# R7FA6M4AF register map
Vendor: Renesas Electronics Corporation; Series: RA6; File version: 1.30.00
CPU: CM33 r0p4, little endian, MPU, FPU, VTOR, 4 interrupt priority bits, 96 interrupts
Registers are 8-bit, read-write, reset 0x0 unless marked. A register's access mark holds for its fields unless they carry their own. Offsets are from the block's base; [hi:lo] are bit positions; {n}, {i} and the like mark numbered series.

## SYSC — System Control
Base 0x4001E000
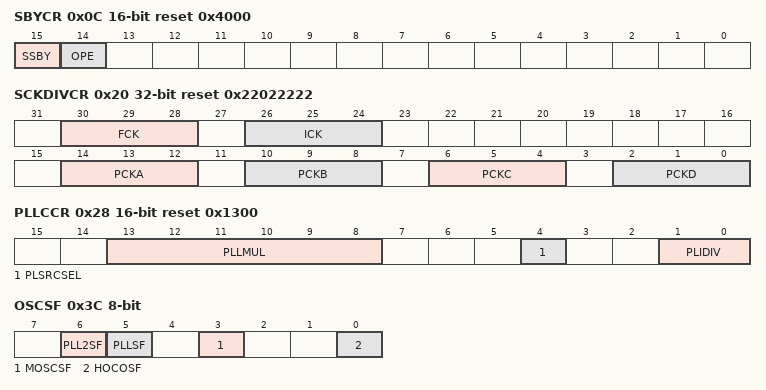
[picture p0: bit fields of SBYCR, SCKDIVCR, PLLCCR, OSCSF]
0x0C SBYCR 16-bit reset 0x4000 — Standby Control Register
  [15] SSBY — Software Standby Mode Select
  [14] OPE — Output Port Enable
0x20 SCKDIVCR 32-bit reset 0x22022222 — System Clock Division Control Register
  [30:28] FCK — FlashIF Clock (FCLK) Select
  [26:24] ICK — System Clock (ICLK) Select
  [14:12] PCKA — Peripheral Module Clock A (PCLKA) Select
  [10:8] PCKB — Peripheral Module Clock B (PCLKB) Select
  [6:4] PCKC — Peripheral Module Clock C (PCLKC) Select
  [2:0] PCKD — Peripheral Module Clock D (PCLKD) Select
0x26 SCKSCR reset 0x1 — System Clock Source Control Register
  [2:0] CKSEL — Clock Source Select
0x28 PLLCCR 16-bit reset 0x1300 — PLL Clock Control Register
  [13:8] PLLMUL range 0x13..0x3B — PLL Frequency Multiplication Factor Select
  [4] PLSRCSEL — PLL Clock Source Select
  [1:0] PLIDIV — PLL Input Frequency Division Ratio Select
0x2A PLLCR reset 0x1 — PLL Control Register
  [0] PLLSTP — PLL Stop Control
0x30 BCKCR — External Bus Clock Control Register
  [0] BCLKDIV — BCLK Pin Output Select
0x32 MOSCCR reset 0x1 — Main Clock Oscillator Control Register
  [0] MOSTP — Main Clock Oscillator Stop
0x36 HOCOCR (reset mask 0xFE) — High,Speed On,Chip Oscillator Control Register
  [0] HCSTP — HOCO Stop
0x38 MOCOCR — Middle,Speed On,Chip Oscillator Control Register
  [0] MCSTP — MOCO Stop
0x39 FLLCR1 — FLL Control Register1
  [0] FLLEN — FLL Enable
0x3A FLLCR2 16-bit — FLL Control Register2
  [10:0] FLLCNTL — FLL Multiplication Control
0x3C OSCSF ro (reset mask 0xFE) — Oscillation Stabilization Flag Register
  [6] PLL2SF — PLL2 Clock Oscillation Stabilization Flag
  [5] PLLSF — PLL Clock Oscillation Stabilization Flag
  [3] MOSCSF — Main Clock Oscillation Stabilization Flag
  [0] HOCOSF — HOCO Clock Oscillation Stabilization Flag
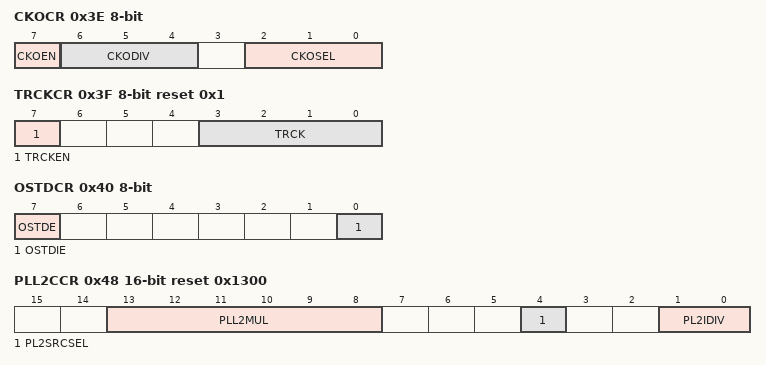
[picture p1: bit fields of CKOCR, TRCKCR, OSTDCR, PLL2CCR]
0x3E CKOCR — Clock Out Control Register
  [7] CKOEN — Clock Out Enable
  [6:4] CKODIV — Clock Output Frequency Division Ratio
  [2:0] CKOSEL — Clock Out Source Select
0x3F TRCKCR reset 0x1 — Trace Clock Control Register
  [7] TRCKEN — Trace Clock operating Enable
  [3:0] TRCK — Trace Clock operating frequency select
0x40 OSTDCR — Oscillation Stop Detection Control Register
  [7] OSTDE — Oscillation Stop Detection Function Enable
  [0] OSTDIE — Oscillation Stop Detection Interrupt Enable
0x41 OSTDSR — Oscillation Stop Detection Status Register
  [0] OSTDF — Oscillation Stop Detection Flag
0x48 PLL2CCR 16-bit reset 0x1300 — PLL2 Clock Control Register
  [13:8] PLL2MUL — PLL2 Frequency Multiplication Factor Select
  [4] PL2SRCSEL — PLL2 Clock Source Select
  [1:0] PL2IDIV — PLL2 Input Frequency Division Ratio Select
0x4A PLL2CR reset 0x1 — PLL2 Control Register
  [0] PLL2STP — PLL2 Stop Control
0x52 EBCKOCR — External Bus Clock Output Control Register
  [0] EBCKOEN — EBCLK Pin Output Control
0x61 MOCOUTCR — MOCO User Trimming Control Register
  [7:0] MOCOUTRM — MOCO User Trimming
0x62 HOCOUTCR — HOCO User Trimming Control Register
  [7:0] HOCOUTRM — HOCO User Trimming
0x6C USBCKDIVCR — USB Clock Division Control Register
  [2:0] USBCKDIV — USB Clock (USBCLK) Division Select
0x6D OCTACKDIVCR — Octal,SPI Clock Division Control Register
  [2:0] OCTACKDIV — Octal,SPI Clock (OCTACLK) Division Select
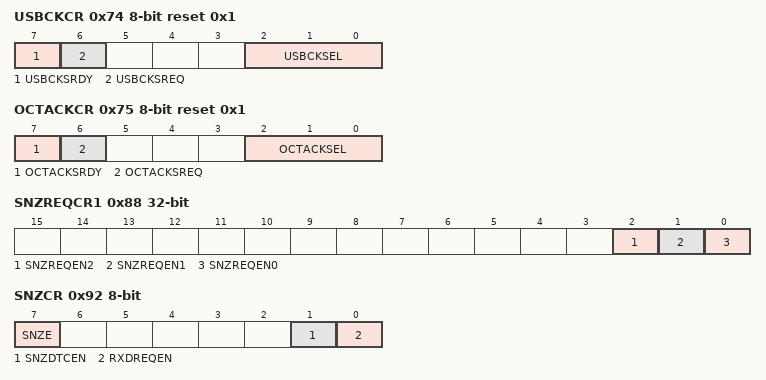
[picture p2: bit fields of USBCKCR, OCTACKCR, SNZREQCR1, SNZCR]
0x74 USBCKCR reset 0x1 — USB Clock Control Register
  [7] USBCKSRDY ro — USB Clock (USBCLK) Switching Ready state flag
  [6] USBCKSREQ — USB Clock (USBCLK) Switching Request
  [2:0] USBCKSEL — USB Clock (USBCLK) Source Select
0x75 OCTACKCR reset 0x1 — Octal,SPI Clock Control Register
  [7] OCTACKSRDY ro — Octal,SPI Clock (OCTACLK) Switching Ready state flag
  [6] OCTACKSREQ — Octal,SPI Clock (OCTACLK) Switching Request
  [2:0] OCTACKSEL — Octal,SPI Clock (OCTACLK) Source Select
0x88 SNZREQCR1 32-bit — Snooze Request Control Register 1
  [2] SNZREQEN2 — Enable AGT3 compare match B snooze request
  [1] SNZREQEN1 — Enable AGT3 compare match A snooze request
  [0] SNZREQEN0 — Enable AGT3 underflow snooze request
0x92 SNZCR — Snooze Control Register
  [7] SNZE — Snooze mode Enable
  [1] SNZDTCEN — DTC Enable in Snooze mode
  [0] RXDREQEN — RXD0 Snooze Request Enable
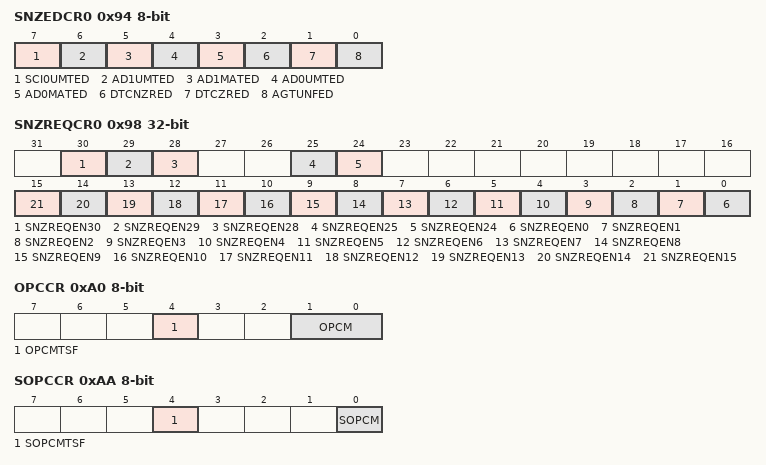
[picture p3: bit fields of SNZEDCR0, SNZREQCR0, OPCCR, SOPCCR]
0x94 SNZEDCR0 — Snooze End Control Register 0
  [7] SCI0UMTED — SCI0 Address Mismatch Snooze End Enable
  [6] AD1UMTED — ADC121 Compare Mismatch Snooze End Enable
  [5] AD1MATED — ADC121 Compare Match Snooze End Enable
  [4] AD0UMTED — ADC120 Compare Mismatch Snooze End Enable
  [3] AD0MATED — ADC120 Compare Match Snooze End Enable
  [2] DTCNZRED — Not Last DTC Transmission Completion Snooze End Enable
  [1] DTCZRED — Last DTC Transmission Completion Snooze End Enable
  [0] AGTUNFED — AGT1 Underflow Snooze End Enable
0x95 SNZEDCR1 — Snooze End Control Register 1
  [0] AGT3UNFED — AGT3 underflow Snooze End Enable
0x98 SNZREQCR0 32-bit — Snooze Request Control Register 0
  [30] SNZREQEN30 — Enable AGT1 compare match B snooze request
  [29] SNZREQEN29 — Enable AGT1 compare match A snooze request
  [28] SNZREQEN28 — Enable AGT1 underflow snooze request
  [25] SNZREQEN25 — Enable RTC period snooze request
  [24] SNZREQEN24 — Enable RTC alarm snooze request
  [n] SNZREQEN{n} (n=0..15) — Enable IRQ{n} pin snooze request
0xA0 OPCCR — Operating Power Control Register
  [4] OPCMTSF ro — Operating Power Control Mode Transition Status Flag
  [1:0] OPCM — Operating Power Control Mode Select
0xA2 MOSCWTCR reset 0x5 — Main Clock Oscillator Wait Control Register
  [3:0] MSTS — Main Clock Oscillator Wait Time Setting
0xAA SOPCCR — Sub Operating Power Control Register
  [4] SOPCMTSF ro — Operating Power Control Mode Transition Status Flag
  [0] SOPCM — Sub Operating Power Control Mode Select
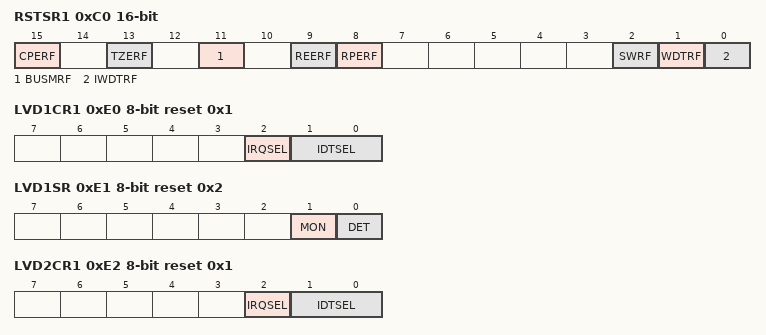
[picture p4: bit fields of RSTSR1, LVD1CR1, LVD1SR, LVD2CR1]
0xC0 RSTSR1 16-bit (reset mask 0x54F8) — Reset Status Register 1
  [15] CPERF — Cache Parity Error Reset Detect Flag
  [13] TZERF — TrustZone Error Reset Detect Flag
  [11] BUSMRF — Bus Master MPU Error Reset Detect Flag
  [9] REERF — SRAM ECC Error Reset Detect Flag
  [8] RPERF — SRAM Parity Error Reset Detect Flag
  [2] SWRF — Software Reset Detect Flag
  [1] WDTRF — Watchdog Timer Reset Detect Flag
  [0] IWDTRF — Independent Watchdog Timer Reset Detect Flag
0xE0 LVD1CR1 reset 0x1 — Voltage Monitor 1 Circuit Control Register
  [2] IRQSEL — Voltage Monitor 1 Interrupt Type Select
  [1:0] IDTSEL — Voltage Monitor 1 Interrupt Generation Condition Select
0xE1 LVD1SR reset 0x2 — Voltage Monitor 1 Circuit Status Register
  [1] MON ro — Voltage Monitor 1 Signal Monitor Flag
  [0] DET — Voltage Monitor 1 Voltage Variation Detection Flag
0xE2 LVD2CR1 reset 0x1 — Voltage Monitor 2 Circuit Control Register 1
  [2] IRQSEL — Voltage Monitor 2 Interrupt Type Select
  [1:0] IDTSEL — Voltage Monitor 2 Interrupt Generation Condition Select
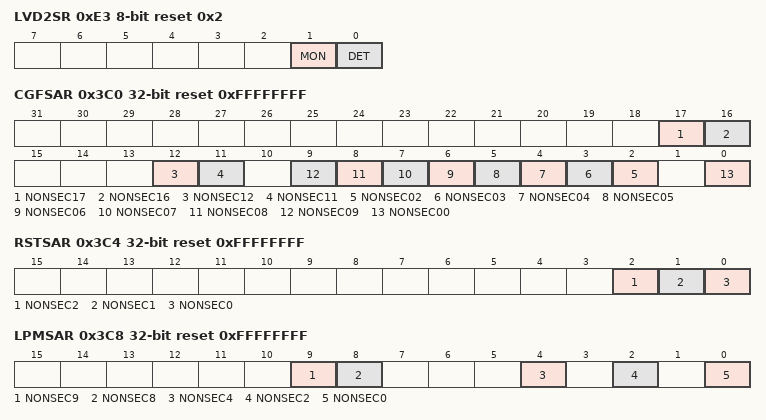
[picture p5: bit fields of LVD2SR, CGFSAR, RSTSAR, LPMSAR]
0xE3 LVD2SR reset 0x2 — Voltage Monitor 2 Circuit Status Register
  [1] MON ro — Voltage Monitor 2 Signal Monitor Flag
  [0] DET — Voltage Monitor 2 Voltage Variation Detection Flag
0x3C0 CGFSAR 32-bit reset 0xFFFFFFFF — Clock Generation Function Security Attribute Register
  [17] NONSEC17 — Non Secure Attribute bit 17
  [16] NONSEC16 — Non Secure Attribute bit 16
  [12] NONSEC12 — Non Secure Attribute bit 12
  [11] NONSEC11 — Non Secure Attribute bit 11
  [n] NONSEC{n:02} (n=2..9) — Non Secure Attribute bit {n:02}
  [0] NONSEC00 — Non Secure Attribute bit 00
0x3C4 RSTSAR 32-bit reset 0xFFFFFFFF — Reset Security Attribution Register
  [2] NONSEC2 — Non Secure Attribute bit 2
  [1] NONSEC1 — Non Secure Attribute bit 1
  [0] NONSEC0 — Non Secure Attribute bit 0
0x3C8 LPMSAR 32-bit reset 0xFFFFFFFF — Low Power Mode Security Attribution Register
  [9] NONSEC9 — Non Secure Attribute bit 9
  [8] NONSEC8 — Non Secure Attribute bit 8
  [4] NONSEC4 — Non Secure Attribute bit 4
  [2] NONSEC2 — Non Secure Attribute bit 2
  [0] NONSEC0 — Non Secure Attribute bit 0
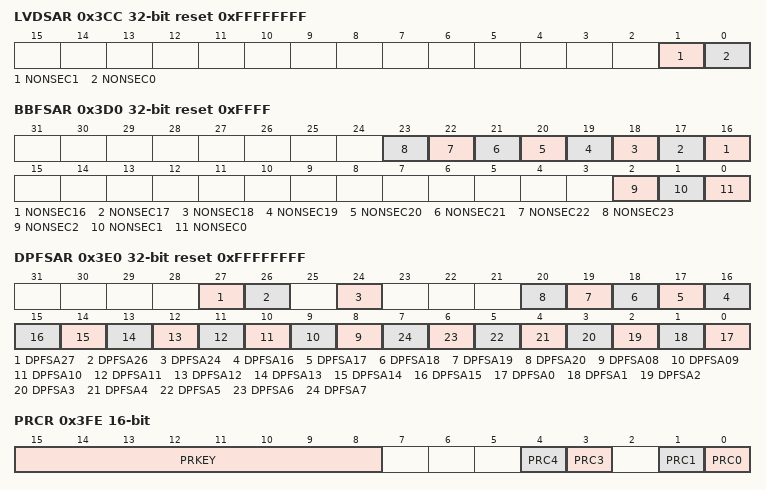
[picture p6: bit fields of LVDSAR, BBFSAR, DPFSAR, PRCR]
0x3CC LVDSAR 32-bit reset 0xFFFFFFFF — Low Voltage Detection Security Attribution Register
  [1] NONSEC1 — Non Secure Attribute bit 1
  [0] NONSEC0 — Non Secure Attribute bit 0
0x3D0 BBFSAR 32-bit reset 0xFFFF — Battery Backup Function Security Attribute Register
  [n] NONSEC{n} (n=16..23) — Non Secure Attribute bit {n}
  [2] NONSEC2 — Non Secure Attribute bit 2
  [1] NONSEC1 — Non Secure Attribute bit 1
  [0] NONSEC0 — Non Secure Attribute bit 0
0x3E0 DPFSAR 32-bit reset 0xFFFFFFFF — Deep Software Standby Interrupt Factor Security Attribution Register
  [27] DPFSA27 — Deep Software Standby Interrupt Factor Security Attribute bit 27
  [26] DPFSA26 — Deep Software Standby Interrupt Factor Security Attribute bit 26
  [24] DPFSA24 — Deep Software Standby Interrupt Factor Security Attribute bit 24
  [n] DPFSA{n} (n=16..20) — Deep Software Standby Interrupt Factor Security Attribute bit {n}
  [n] DPFSA{n:02} (n=8..15) — Deep Software Standby Interrupt Factor Security Attribute bit n (n = 8 to 15)
  [n] DPFSA{n} (n=0..7) — Deep Software Standby Interrupt Factor Security Attribute bit n (n = 0 to 7)
0x3FE PRCR 16-bit — Protect Register
  [15:8] PRKEY wo — PRC Key Code
  [4] PRC4
  [3] PRC3 — Enable writing to the registers related to the LVD
  [1] PRC1 — Enable writing to the registers related to the low power modes, and the battery backup function
  [0] PRC0 — Enable writing to the registers related to the clock generation circuit
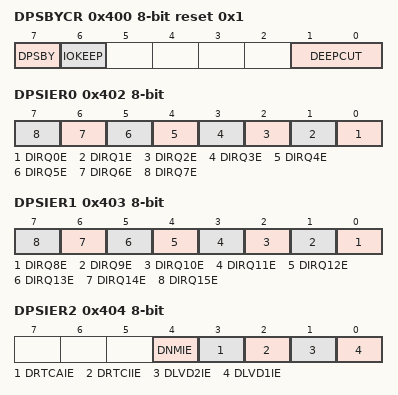
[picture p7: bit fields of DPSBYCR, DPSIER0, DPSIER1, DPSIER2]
0x400 DPSBYCR reset 0x1 — Deep Software Standby Control Register
  [7] DPSBY — Deep Software Standby
  [6] IOKEEP — I/O Port Retention
  [1:0] DEEPCUT — Power,Supply Control
0x401 DPSWCR reset 0x19 — Deep Software Standby Wait Control Register
  [5:0] WTSTS — Deep Software Wait Standby Time Setting Bit
0x402 DPSIER0 — Deep Software Standby Interrupt Enable Register 0
  [n] DIRQ{n}E (n=0..7) — IRQ{n}-DS Pin Enable
0x403 DPSIER1 — Deep Software Standby Interrupt Enable Register 1
  [n-8] DIRQ{n}E (n=8..15) — IRQ{n}-DS Pin Enable
0x404 DPSIER2 — Deep Software Standby Interrupt Enable Register 2
  [4] DNMIE — NMI Pin Enable
  [3] DRTCAIE — RTC Alarm interrupt Deep Software Standby Cancel Signal Enable
  [2] DRTCIIE — RTC Interval interrupt Deep Software Standby Cancel Signal Enable
  [1] DLVD2IE — LVD2 Deep Software Standby Cancel Signal Enable
  [0] DLVD1IE — LVD1 Deep Software Standby Cancel Signal Enable
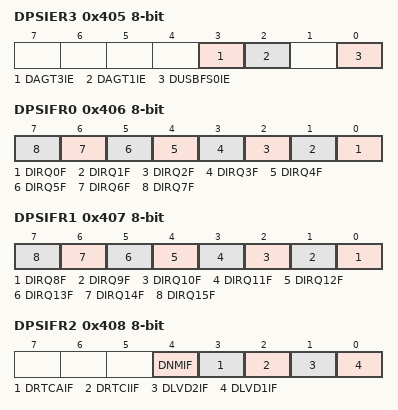
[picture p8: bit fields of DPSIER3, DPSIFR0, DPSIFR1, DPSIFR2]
0x405 DPSIER3 — Deep Software Standby Interrupt Enable Register 3
  [3] DAGT3IE — AGT3 Underflow Deep Software Standby Cancel Signal Enable
  [2] DAGT1IE — AGT1 Underflow Deep Software Standby Cancel Signal Enable
  [0] DUSBFS0IE — USBFS0 Suspend/Resume Deep Software Standby Cancel Signal Enable
0x406 DPSIFR0 — Deep Software Standby Interrupt Flag Register 0
  [n] DIRQ{n}F (n=0..7) — IRQ{n}-DS Pin Deep Software Standby Cancel Flag
0x407 DPSIFR1 — Deep Software Standby Interrupt Flag Register 1
  [n-8] DIRQ{n}F (n=8..15) — IRQ{n}-DS Pin Deep Software Standby Cancel Flag
0x408 DPSIFR2 — Deep Software Standby Interrupt Flag Register 2
  [4] DNMIF — NMI Pin Deep Software Standby Cancel Flag
  [3] DRTCAIF — RTC Alarm Interrupt Deep Software Standby Cancel Flag
  [2] DRTCIIF — RTC Interval Interrupt Deep Software Standby Cancel Flag
  [1] DLVD2IF — LVD2 Deep Software Standby Cancel Flag
  [0] DLVD1IF — LVD1 Deep Software Standby Cancel Flag
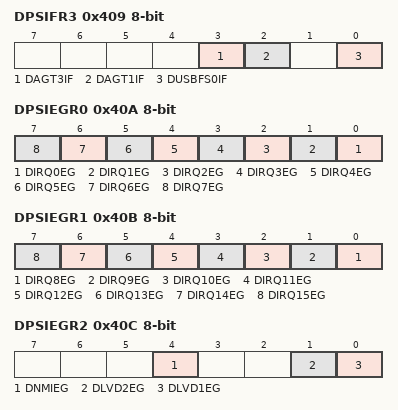
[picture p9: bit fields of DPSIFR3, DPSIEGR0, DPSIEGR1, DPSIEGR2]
0x409 DPSIFR3 — Deep Software Standby Interrupt Flag Register 3
  [3] DAGT3IF — AGT3 Underflow Deep Software Standby Cancel Flag
  [2] DAGT1IF — AGT1 Underflow Deep Software Standby Cancel Flag
  [0] DUSBFS0IF — USBFS0 Suspend/Resume Deep Software Standby Cancel Flag
0x40A DPSIEGR0 — Deep Software Standby Interrupt Edge Register 0
  [n] DIRQ{n}EG (n=0..7) — IRQ{n}-DS Pin Edge Select
0x40B DPSIEGR1 — Deep Software Standby Interrupt Edge Register 1
  [n-8] DIRQ{n}EG (n=8..15) — IRQ{n}-DS Pin Edge Select
0x40C DPSIEGR2 — Deep Software Standby Interrupt Edge Register 2
  [4] DNMIEG — NMI Pin Edge Select
  [1] DLVD2EG — LVD2 Edge Select
  [0] DLVD1EG — LVD1 Edge Select
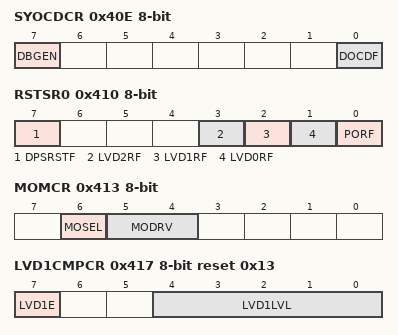
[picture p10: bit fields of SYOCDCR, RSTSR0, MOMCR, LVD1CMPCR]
0x40E SYOCDCR (reset mask 0xFE) — System Control OCD Control Register
  [7] DBGEN — Debugger Enable bit
  [0] DOCDF — Deep Software Standby OCD flag
0x410 RSTSR0 (reset mask 0x70) — Reset Status Register 0
  [7] DPSRSTF — Deep Software Standby Reset Detect Flag
  [3] LVD2RF — Voltage Monitor 2 Reset Detect Flag
  [2] LVD1RF — Voltage Monitor 1 Reset Detect Flag
  [1] LVD0RF — Voltage Monitor 0 Reset Detect Flag
  [0] PORF — Power,On Reset Detect Flag
0x411 RSTSR2 (reset mask 0xFE) — Reset Status Register 2
  [0] CWSF — Cold/Warm Start Determination Flag
0x413 MOMCR — Main Clock Oscillator Mode Oscillation Control Register
  [6] MOSEL — Main Clock Oscillator Switching
  [5:4] MODRV — Main Clock Oscillator Drive Capability 0 Switching
0x416 FWEPROR reset 0x2 — Flash P/E Protect Register
  [1:0] FLWE — Flash Programming and Erasure
0x417 LVD1CMPCR reset 0x13 — Voltage Monitoring 1 Comparator Control Register
  [7] LVD1E — Voltage Detection 1 Enable
  [4:0] LVD1LVL — Voltage Detection 1 Level Select (Standard voltage during drop in voltage)
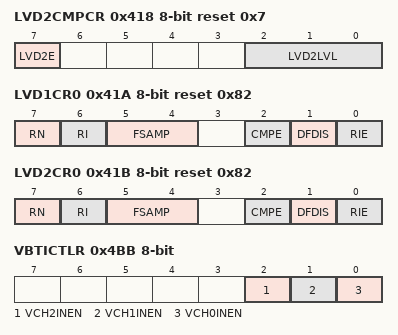
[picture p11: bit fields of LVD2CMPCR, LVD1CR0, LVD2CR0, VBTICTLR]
0x418 LVD2CMPCR reset 0x7 — Voltage Monitoring 2 Comparator Control Register
  [7] LVD2E — Voltage Detection 2 Enable
  [2:0] LVD2LVL — Voltage Detection 2 Level Select (Standard voltage during drop in voltage)
0x41A LVD1CR0 reset 0x82 — Voltage Monitor 1 Circuit Control Register 0
  [7] RN — Voltage Monitor 1 Reset Negate Select
  [6] RI — Voltage Monitor 1 Circuit Mode Select
  [5:4] FSAMP — Sampling Clock Select
  [2] CMPE — Voltage Monitor 1 Circuit Comparison Result Output Enable
  [1] DFDIS — Voltage monitor 1 Digital Filter Disabled Mode Select
  [0] RIE — Voltage Monitor 1 Interrupt/Reset Enable
0x41B LVD2CR0 reset 0x82 — Voltage Monitor 2 Circuit Control Register 0
  [7] RN — Voltage Monitor 2 Reset Negate Select
  [6] RI — Voltage Monitor 2 Circuit Mode Select
  [5:4] FSAMP — Sampling Clock Select
  [2] CMPE — Voltage Monitor 2 Circuit Comparison Result Output Enable
  [1] DFDIS — Voltage monitor 2 Digital Filter Disabled Mode Select
  [0] RIE — Voltage Monitor 2 Interrupt/Reset Enable
0x41D VBATTMNSELR — Battery Backup Voltage Monitor Function Select Register
  [0] VBATTMNSEL — VBATT Low Voltage Detect Function Select Bit
0x41E VBATTMONR ro — Battery Backup Voltage Monitor Register
  [0] VBATTMON — VBATT Voltage Monitor Bit
0x480 SOSCCR — Sub,Clock Oscillator Control Register
  [0] SOSTP — Sub Clock Oscillator Stop
0x481 SOMCR — Sub,Clock Oscillator Mode Control Register
  [1] SODRV — Sub,Clock Oscillator Drive Capability Switching
0x490 LOCOCR — Low,Speed On,Chip Oscillator Control Register
  [0] LCSTP — LOCO Stop
0x492 LOCOUTCR — LOCO User Trimming Control Register
  [7:0] LOCOUTRM — LOCO User Trimming
0x4BB VBTICTLR (reset mask 0xF8) — VBATT Input Control Register
  [2] VCH2INEN — VBATT CH2 Input Enable
  [1] VCH1INEN — VBATT CH1 Input Enable
  [0] VCH0INEN — VBATT CH0 Input Enable
0x4C0 VBTBER reset 0x8 — VBATT Backup Enable Register
  [3] VBAE — VBATT backup register access enable bit
{0x500+i} VBTBKR[{i}] (i=0..127) reset not defined — VBATT Backup Register
  [7:0] VBTBKR
